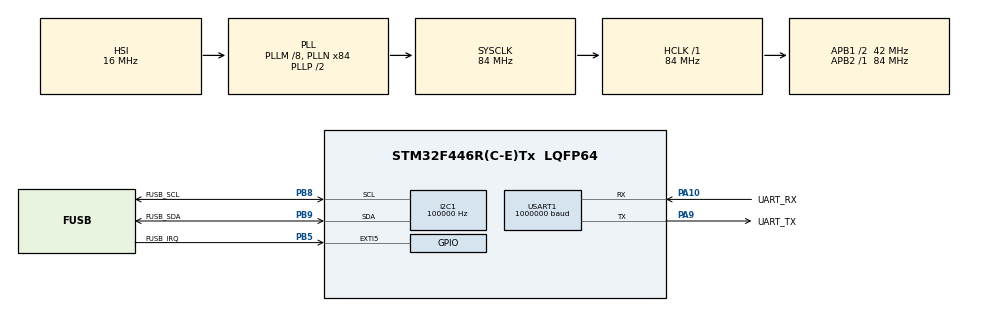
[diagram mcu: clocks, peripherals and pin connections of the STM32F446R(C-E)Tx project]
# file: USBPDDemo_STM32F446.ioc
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Dma.I2C1_RX.0.Direction=DMA_PERIPH_TO_MEMORY
Dma.I2C1_RX.0.FIFOMode=DMA_FIFOMODE_DISABLE
Dma.I2C1_RX.0.Instance=DMA1_Stream0
Dma.I2C1_RX.0.MemDataAlignment=DMA_MDATAALIGN_BYTE
Dma.I2C1_RX.0.MemInc=DMA_MINC_ENABLE
Dma.I2C1_RX.0.Mode=DMA_NORMAL
Dma.I2C1_RX.0.PeriphDataAlignment=DMA_PDATAALIGN_BYTE
Dma.I2C1_RX.0.PeriphInc=DMA_PINC_DISABLE
Dma.I2C1_RX.0.Priority=DMA_PRIORITY_LOW
Dma.I2C1_TX.1.Direction=DMA_MEMORY_TO_PERIPH
Dma.I2C1_TX.1.FIFOMode=DMA_FIFOMODE_DISABLE
Dma.I2C1_TX.1.Instance=DMA1_Stream6
Dma.I2C1_TX.1.MemDataAlignment=DMA_MDATAALIGN_BYTE
Dma.I2C1_TX.1.MemInc=DMA_MINC_ENABLE
Dma.I2C1_TX.1.Mode=DMA_NORMAL
Dma.I2C1_TX.1.PeriphDataAlignment=DMA_PDATAALIGN_BYTE
Dma.I2C1_TX.1.PeriphInc=DMA_PINC_DISABLE
Dma.I2C1_TX.1.Priority=DMA_PRIORITY_LOW
Dma.Request0=I2C1_RX
Dma.Request1=I2C1_TX
Dma.Request2=USART1_TX
Dma.Request3=USART1_RX
Dma.USART1_RX.3.Direction=DMA_PERIPH_TO_MEMORY
Dma.USART1_RX.3.FIFOMode=DMA_FIFOMODE_DISABLE
Dma.USART1_RX.3.Instance=DMA2_Stream2
Dma.USART1_RX.3.MemDataAlignment=DMA_MDATAALIGN_BYTE
Dma.USART1_RX.3.MemInc=DMA_MINC_ENABLE
Dma.USART1_RX.3.Mode=DMA_NORMAL
Dma.USART1_RX.3.PeriphDataAlignment=DMA_PDATAALIGN_BYTE
Dma.USART1_RX.3.PeriphInc=DMA_PINC_DISABLE
Dma.USART1_RX.3.Priority=DMA_PRIORITY_LOW
Dma.USART1_TX.2.Direction=DMA_MEMORY_TO_PERIPH
Dma.USART1_TX.2.FIFOMode=DMA_FIFOMODE_DISABLE
Dma.USART1_TX.2.Instance=DMA2_Stream7
Dma.USART1_TX.2.MemDataAlignment=DMA_MDATAALIGN_BYTE
Dma.USART1_TX.2.MemInc=DMA_MINC_ENABLE
Dma.USART1_TX.2.Mode=DMA_NORMAL
Dma.USART1_TX.2.PeriphDataAlignment=DMA_PDATAALIGN_BYTE
Dma.USART1_TX.2.PeriphInc=DMA_PINC_DISABLE
Dma.USART1_TX.2.Priority=DMA_PRIORITY_LOW
I2C1.AddressingMode=I2C_ADDRESSINGMODE_7BIT
I2C1.ClockSpeed=100000
I2C1.DualAddressMode=I2C_DUALADDRESS_DISABLE
I2C1.GeneralCallMode=I2C_GENERALCALL_DISABLE
I2C1.I2C_Mode=I2C_Standard
I2C1.NoStretchMode=I2C_NOSTRETCH_DISABLE
I2C1.OwnAddress=0
Mcu.Family=STM32F4
Mcu.Name=STM32F446R(C-E)Tx
Mcu.Package=LQFP64
NVIC.DMA1_Stream0_IRQn=true\:0\:0\:false\:false\:true\:false\:true\:true
NVIC.DMA1_Stream6_IRQn=true\:0\:0\:false\:false\:true\:false\:true\:true
NVIC.DMA2_Stream2_IRQn=true\:0\:0\:false\:false\:true\:false\:true\:true
NVIC.DMA2_Stream7_IRQn=true\:0\:0\:false\:false\:true\:false\:true\:true
NVIC.I2C1_ER_IRQn=true\:0\:0\:false\:false\:true\:true\:true\:true
NVIC.I2C1_EV_IRQn=true\:0\:0\:false\:false\:true\:true\:true\:true
NVIC.PriorityGroup=NVIC_PRIORITYGROUP_4
NVIC.USART1_IRQn=true\:0\:0\:false\:false\:true\:true\:true\:true
PA10.GPIO_Label=UART_RX
PA10.Mode=Asynchronous
PA10.Signal=USART1_RX
PA13.GPIO_Label=SWDIO
PA13.Mode=Serial_Wire
PA13.Signal=SYS_JTMS-SWDIO
PA14.GPIO_Label=SWCLK
PA14.Mode=Serial_Wire
PA14.Signal=SYS_JTCK-SWCLK
PA9.GPIO_Label=UART_TX
PA9.Mode=Asynchronous
PA9.Signal=USART1_TX
PB5.GPIO_Label=FUSB_IRQ
PB5.Signal=GPXTI5
PB8.GPIO_Label=FUSB_SCL
PB8.GPIO_Pu=GPIO_PULLUP
PB8.Mode=I2C
PB8.Signal=I2C1_SCL
PB9.GPIO_Label=FUSB_SDA
PB9.GPIO_Pu=GPIO_PULLUP
PB9.Mode=I2C
PB9.Signal=I2C1_SDA
PH0-OSC_IN.Mode=HSE-External-Oscillator
PH0-OSC_IN.Signal=RCC_OSC_IN
PH1-OSC_OUT.Mode=HSE-External-Oscillator
PH1-OSC_OUT.Signal=RCC_OSC_OUT
ProjectManager.HeapSize=0x200
ProjectManager.StackSize=0x400
ProjectManager.TargetToolchain=STM32CubeIDE
RCC.AHBFreq_Value=84000000
RCC.APB1CLKDivider=RCC_HCLK_DIV2
RCC.APB1Freq_Value=42000000
RCC.APB1TimFreq_Value=84000000
RCC.APB2Freq_Value=84000000
RCC.APB2TimFreq_Value=84000000
RCC.CortexFreq_Value=84000000
RCC.FLatency=FLASH_LATENCY_2
RCC.HCLKFreq_Value=84000000
RCC.PLLM=8
RCC.PLLN=84
RCC.PWR_Regulator_Voltage_Scale=PWR_REGULATOR_VOLTAGE_SCALE2
RCC.SYSCLKFreq_VALUE=84000000
RCC.SYSCLKSource=RCC_SYSCLKSOURCE_PLLCLK
RCC.USBFreq_Value=84000000
RCC.VCOOutputFreq_Value=168000000
USART1.BaudRate=1000000
USART1.Mode=MODE_TX_RX
USART1.OverSampling=UART_OVERSAMPLING_16
USART1.Parity=PARITY_NONE
USART1.StopBits=STOPBITS_1
USART1.VirtualMode=VM_ASYNC
USART1.WordLength=WORDLENGTH_8B
board=custom

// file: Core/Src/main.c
/* USER CODE BEGIN Header */
/**
  ******************************************************************************
  * @file           : main.c
  * @brief          : Main program body
  ******************************************************************************
  * @attention
  *
  * Copyright (c) 2023 STMicroelectronics.
  * All rights reserved.
  *
  * This software is licensed under terms that can be found in the LICENSE file
  * in the root directory of this software component.
  * If no LICENSE file comes with this software, it is provided AS-IS.
  *
  ******************************************************************************
  */
/* USER CODE END Header */
#include "main.h"
#include "dma.h"
#include "i2c.h"
#include "usart.h"
#include "gpio.h"

/* USER CODE BEGIN Includes */
#include "PDUser.h"
#include "stdio.h"
/* USER CODE END Includes */

void SystemClock_Config(void);

int main(void)
{

  /* MCU Configuration--------------------------------------------------------*/

  /* Reset of all peripherals, Initializes the Flash interface and the Systick. */
  HAL_Init();

  /* Configure the system clock */
  SystemClock_Config();

  /* Initialize all configured peripherals */
  MX_GPIO_Init();
  MX_DMA_Init();
  MX_I2C1_Init();
  MX_USART1_UART_Init();
  /* USER CODE BEGIN 2 */
  printf("Starting\r\n");
  pd_user_main();
  /* USER CODE END 2 */

  /* Infinite loop */
  while (1)
  {

  }
}

void SystemClock_Config(void)
{
  RCC_OscInitTypeDef RCC_OscInitStruct = {0};
  RCC_ClkInitTypeDef RCC_ClkInitStruct = {0};

  /** Configure the main internal regulator output voltage
  */
  __HAL_RCC_PWR_CLK_ENABLE();
  __HAL_PWR_VOLTAGESCALING_CONFIG(PWR_REGULATOR_VOLTAGE_SCALE2);

  /** Initializes the RCC Oscillators according to the specified parameters
  * in the RCC_OscInitTypeDef structure.
  */
  RCC_OscInitStruct.OscillatorType = RCC_OSCILLATORTYPE_HSI;
  RCC_OscInitStruct.HSIState = RCC_HSI_ON;
  RCC_OscInitStruct.HSICalibrationValue = RCC_HSICALIBRATION_DEFAULT;
  RCC_OscInitStruct.PLL.PLLState = RCC_PLL_ON;
  RCC_OscInitStruct.PLL.PLLSource = RCC_PLLSOURCE_HSI;
  RCC_OscInitStruct.PLL.PLLM = 8;
  RCC_OscInitStruct.PLL.PLLN = 84;
  RCC_OscInitStruct.PLL.PLLP = RCC_PLLP_DIV2;
  RCC_OscInitStruct.PLL.PLLQ = 2;
  RCC_OscInitStruct.PLL.PLLR = 2;
  if (HAL_RCC_OscConfig(&RCC_OscInitStruct) != HAL_OK)
  {
    Error_Handler();
  }

  /** Initializes the CPU, AHB and APB buses clocks
  */
  RCC_ClkInitStruct.ClockType = RCC_CLOCKTYPE_HCLK|RCC_CLOCKTYPE_SYSCLK
                              |RCC_CLOCKTYPE_PCLK1|RCC_CLOCKTYPE_PCLK2;
  RCC_ClkInitStruct.SYSCLKSource = RCC_SYSCLKSOURCE_PLLCLK;
  RCC_ClkInitStruct.AHBCLKDivider = RCC_SYSCLK_DIV1;
  RCC_ClkInitStruct.APB1CLKDivider = RCC_HCLK_DIV2;
  RCC_ClkInitStruct.APB2CLKDivider = RCC_HCLK_DIV1;

  if (HAL_RCC_ClockConfig(&RCC_ClkInitStruct, FLASH_LATENCY_2) != HAL_OK)
  {
    Error_Handler();
  }
}

void Error_Handler(void)
{
  __disable_irq();
  while (1)
  {
  }
}
